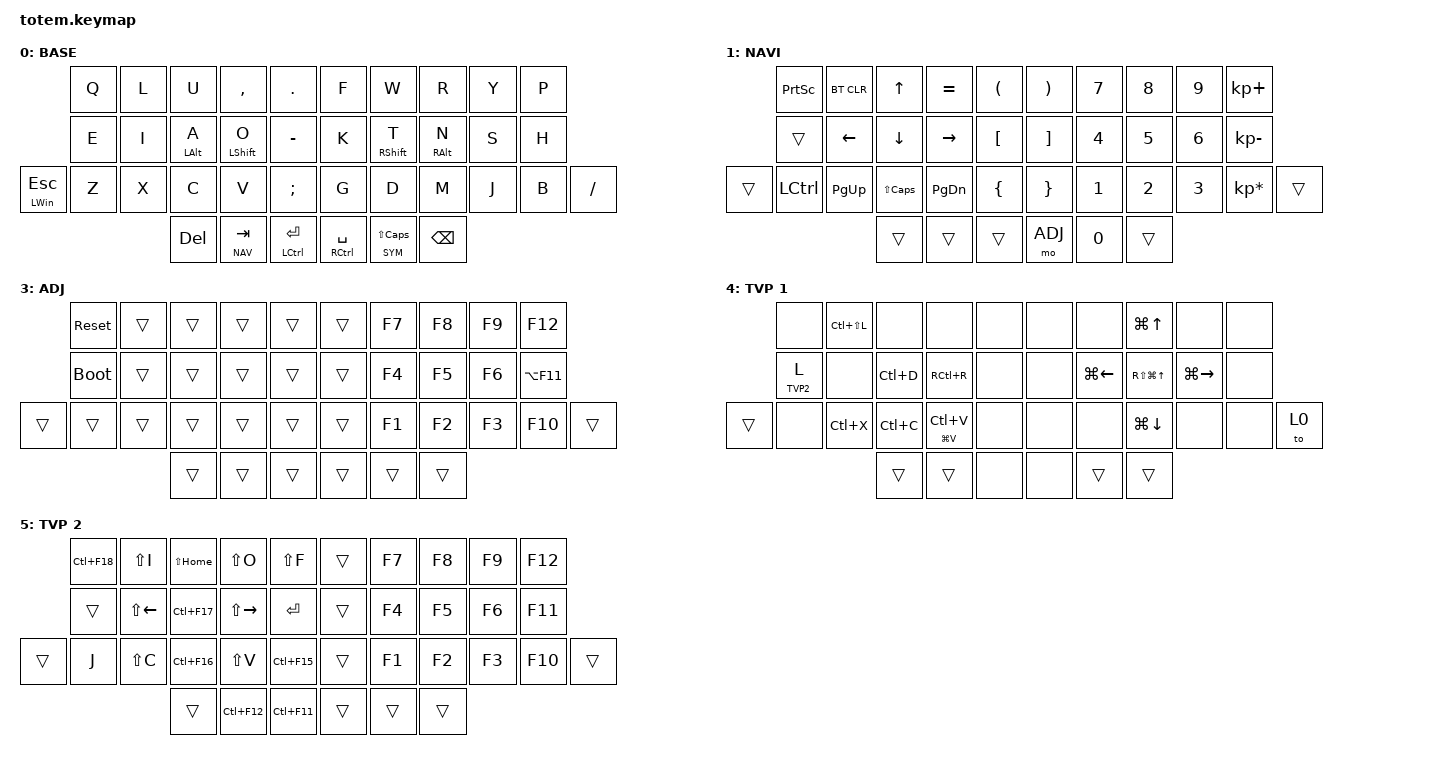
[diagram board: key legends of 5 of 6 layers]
//
//                                                        ▀▀▀▀▀     ▀▀▀▀▀          ▀▀█▀▀
//                                                        ▄▀▀▀▄  ▄  ▄▀▀▀▄  ▄  ▄▀▀▀▄  █  ▄▀▀▀▄
//                                                        █   █  █  █   █  █  █   █  █  █   █
//                                                         ▀▀▀   █   ▀▀▀   █   ▀▀▀   ▀   ▀▀▀
//                                                               █      ▄▄▄█▄▄▄    █   █  
//                                                               ▀      █  █  █     █▄█
//                                                             ▀▀▀▀▀    █  █  █      ▀
//                                                                      ▀  ▀  ▀
//
// ▄▄▄▄▄▄▄▄▄▄▄▄▄▄▄▄▄▄▄▄▄▄▄▄▄▄▄▄▄▄▄▄▄▄▄▄▄▄▄▄▄▄▄▄▄▄▄▄▄▄▄▄▄▄▄▄▄▄▄▄▄▄▄▄▄▄▄▄▄▄▄▄▄▄▄▄▄▄▄▄▄▄▄▄▄▄▄▄▄▄▄▄▄▄▄▄▄▄▄▄▄▄▄▄▄▄▄▄▄▄▄▄▄▄▄▄▄▄▄▄▄▄▄▄▄▄▄▄▄▄▄▄▄▄▄▄▄▄▄▄▄▄▄▄▄▄▄▄▄

#include <behaviors.dtsi>
#include <dt-bindings/zmk/bt.h>
#include <dt-bindings/zmk/keys.h>

#define BASE 0
#define NAV  1
#define SYM  2
#define ADJ  3
#define TVP1 4
#define TVP2 5

&mt {
    quick-tap-ms = <300>;
    global-quick-tap;
    flavor = "tap-preferred";
    tapping-term-ms = <325>;
};

/ {
    combos {
        compatible = "zmk,combos";

        Input_my_PW {
            bindings = <&my_PW>;
            key-positions = <14 15>;
        };

        L0 {
            bindings = <&to 0>;
            key-positions = <10 19>;
        };

        L4 {
            timeout-ms = <100>;
            key-positions = <11 12 13>;
            bindings = <&tog TVP1>;
        };

        ab12 {
            bindings = <&kp LANGUAGE_2>;
            key-positions = <12 13>;
        };

        Hiragana {
            bindings = <&kp LANGUAGE_1>;
            key-positions = <16 17>;
        };

        Orchis {
            bindings = <&kp LC(LA(SPACE))>;
            key-positions = <34 35>;
        };

        TaskMgr {
            bindings = <&kp LC(LS(ESCAPE))>;
            key-positions = <20 31>;
        };

        BT0 {
            bindings = <&bt BT_SEL 0>;
            key-positions = <5 6>;
        };

        BT1 {
            bindings = <&bt BT_SEL 1>;
            key-positions = <15 16>;
        };

        BT2 {
            bindings = <&bt BT_SEL 2>;
            key-positions = <26 27>;
        };

        BT3 {
            bindings = <&bt BT_SEL 3>;
            key-positions = <3 4>;
        };

        egaty1975 {
            bindings = <&egaty1975>;
            key-positions = <4 5>;
        };

        ns_xn {
            bindings = <&ns_xn>;
            key-positions = <17 18>;
        };
    };

    macros {
        my_PW: my_PW {
            compatible = "zmk,behavior-macro";
            #binding-cells = <0>;
            bindings =
                <&macro_tap>,
                <&kp N9 &kp N0 &kp N8 &kp LS(Z) &kp LS(X) &kp LS(C) &kp LS(V) &kp LS(N1) &kp Z &kp X &kp C &kp V>;

            label = "my_PW";
        };

        egaty1975: egaty1975 {
            compatible = "zmk,behavior-macro";
            #binding-cells = <0>;
            bindings =
                <&macro_tap>,
                <&kp N6 &kp N5 &kp N4 &kp Z &kp X &kp C &kp V &kp LS(Z) &kp LS(X) &kp LS(C) &kp LS(V) &kp LS(N1)>;

            label = "EGATY1975";
        };

        ns_xn: ns_xn {
            compatible = "zmk,behavior-macro";
            #binding-cells = <0>;
            bindings = <&macro_tap>, <&kp X &kp N>;

            label = "NS_XN";
        };
    };

    keymap {
        compatible = "zmk,keymap";

        // ▄▄▄▄▄▄▄▄▄▄▄▄▄▄▄▄▄▄▄▄▄▄▄▄▄▄▄▄▄▄▄▄▄▄▄▄▄▄▄▄▄▄▄▄▄▄▄▄▄▄▄▄▄▄▄▄▄▄▄▄▄▄▄▄▄▄▄▄▄▄▄▄▄▄▄▄▄▄▄▄▄▄▄▄▄▄▄▄▄▄▄▄▄▄▄▄▄▄▄▄▄▄▄▄▄▄▄▄▄▄▄▄▄▄▄▄▄▄▄▄▄▄▄▄▄▄▄▄▄▄▄▄▄▄▄▄▄▄▄▄▄▄▄▄▄▄▄▄▄

        base_layer {
            // ┏━━━━━━━━━━━━━━━━━━━━━━━━━━━━━━━━━━━━━━━┓

            label = "BASE";

            // ┗━━━━━━━━━━━━━━━━━━━━━━━━━━━━━━━━━━━━━━━┛
            //             ┏━━━━━━━━━━━┳━━━━━━━━━━━┳━━━━━━━━━━━┳━━━━━━━━━━━┳━━━━━━━━━━━┓   ┏━━━━━━━━━━━┳━━━━━━━━━━━┳━━━━━━━━━━━┳━━━━━━━━━━━┳━━━━━━━━━━━┓
            //             ┃     Q     ┃     W     ┃     F     ┃     P     ┃     G     ┃   ┃     J     ┃     L     ┃     U     ┃     Y     ┃     ;     ┃
            //             ┣━━━━━━━━━━━╋━━━━━━━━━━━╋━━━━━━━━━━━╋━━━━━━━━━━━╋━━━━━━━━━━━┫   ┣━━━━━━━━━━━╋━━━━━━━━━━━╋━━━━━━━━━━━╋━━━━━━━━━━━╋━━━━━━━━━━━┫
            //             ┃     A     ┃     R     ┃     S     ┃     T     ┃     D     ┃   ┃     H     ┃     N     ┃     E     ┃     I     ┃     O     ┃
            // ┏━━━━━━━━━━━╋━━━━━━━━━━━╋━━━━━━━━━━━╋━━━━━━━━━━━╋━━━━━━━━━━━╋━━━━━━━━━━━┫   ┣━━━━━━━━━━━╋━━━━━━━━━━━╋━━━━━━━━━━━╋━━━━━━━━━━━╋━━━━━━━━━━━╋━━━━━━━━━━━┓
            // ┃     Q     ┃     Z     ┃     X     ┃     C     ┃     V     ┃     B     ┃   ┃     K     ┃     M     ┃     ,     ┃     .     ┃     /     ┃     \     ┃
            // ┗━━━━━━━━━━━┻━━━━━━━━━━━┻━━━━━━━━━━━╋━━━━━━━━━━━╋━━━━━━━━━━━╋━━━━━━━━━━━┫   ┣━━━━━━━━━━━╋━━━━━━━━━━━╋━━━━━━━━━━━╋━━━━━━━━━━━┻━━━━━━━━━━━┻━━━━━━━━━━━┛
            //                                     ┃    DEL    ┃    TAB    ┃    SPC    ┃   ┃   ENTER   ┃           ┃   BSPC    ┃
            //                                     ┗━━━━━━━━━━━┻━━━━━━━━━━━┻━━━━━━━━━━━┛   ┗━━━━━━━━━━━┻━━━━━━━━━━━┻━━━━━━━━━━━┛

            bindings = <
                  &kp Q  &kp L  &kp U           &kp COMMA         &kp PERIOD              &kp F                    &kp W              &kp R            &kp Y  &kp P
                  &kp E  &kp I  &mt LEFT_ALT A  &mt LEFT_SHIFT O  &kp MINUS               &kp K                    &mt RIGHT_SHIFT T  &mt RIGHT_ALT N  &kp S  &kp H
&mt LEFT_WIN ESC  &kp Z  &kp X  &kp C           &kp V             &kp SEMICOLON           &kp G                    &kp D              &kp M            &kp J  &kp B  &kp SLASH
                                &kp DELETE      &lt NAV TAB       &mt LEFT_CONTROL RET    &mt RIGHT_CONTROL SPACE  &lt SYM LS(CAPS)   &kp BSPC
            >;
        };

        // ▄▄▄▄▄▄▄▄▄▄▄▄▄▄▄▄▄▄▄▄▄▄▄▄▄▄▄▄▄▄▄▄▄▄▄▄▄▄▄▄▄▄▄▄▄▄▄▄▄▄▄▄▄▄▄▄▄▄▄▄▄▄▄▄▄▄▄▄▄▄▄▄▄▄▄▄▄▄▄▄▄▄▄▄▄▄▄▄▄▄▄▄▄▄▄▄▄▄▄▄▄▄▄▄▄▄▄▄▄▄▄▄▄▄▄▄▄▄▄▄▄▄▄▄▄▄▄▄▄▄▄▄▄▄▄▄▄▄▄▄▄▄▄▄▄▄▄▄▄

        nav_layer {
            // ┏━━━━━━━━━━━━━━━━━━━━━━━━━━━━━━━━━━━━━━━┓

            label = "NAVI";

            // ┗━━━━━━━━━━━━━━━━━━━━━━━━━━━━━━━━━━━━━━━┛
            //             ┏━━━━━━━━━━━┳━━━━━━━━━━━┳━━━━━━━━━━━┳━━━━━━━━━━━┳━━━━━━━━━━━┓   ┏━━━━━━━━━━━┳━━━━━━━━━━━┳━━━━━━━━━━━┳━━━━━━━━━━━┳━━━━━━━━━━━┓
            //             ┃           ┃           ┃     UP    ┃           ┃     {     ┃   ┃     }     ┃     7     ┃     8     ┃     9     ┃     +     ┃
            //             ┣━━━━━━━━━━━╋━━━━━━━━━━━╋━━━━━━━━━━━╋━━━━━━━━━━━╋━━━━━━━━━━━┫   ┣━━━━━━━━━━━╋━━━━━━━━━━━╋━━━━━━━━━━━╋━━━━━━━━━━━╋━━━━━━━━━━━┫
            //             ┃   SHIFT   ┃   LEFT    ┃    DOWN   ┃   RIGHT   ┃     [     ┃   ┃     ]     ┃     4     ┃     5     ┃     6     ┃     -     ┃
            // ┏━━━━━━━━━━━╋━━━━━━━━━━━╋━━━━━━━━━━━╋━━━━━━━━━━━╋━━━━━━━━━━━╋━━━━━━━━━━━┫   ┣━━━━━━━━━━━╋━━━━━━━━━━━╋━━━━━━━━━━━╋━━━━━━━━━━━╋━━━━━━━━━━━╋━━━━━━━━━━━┓
            // ┃           ┃           ┃   P UP    ┃  C LOCK   ┃  P DOWN   ┃     (     ┃   ┃     )     ┃     1     ┃     2     ┃     3     ┃     *     ┃           ┃
            // ┗━━━━━━━━━━━┻━━━━━━━━━━━┻━━━━━━━━━━━╋━━━━━━━━━━━╋━━━━━━━━━━━╋━━━━━━━━━━━┫   ┣━━━━━━━━━━━╋━━━━━━━━━━━╋━━━━━━━━━━━╋━━━━━━━━━━━┻━━━━━━━━━━━┻━━━━━━━━━━━┛
            //                                     ┃           ┃    TAB    ┃    SPC    ┃   ┃    DEL    ┃     0     ┃           ┃
            //                                     ┗━━━━━━━━━━━┻━━━━━━━━━━━┻━━━━━━━━━━━┛   ┗━━━━━━━━━━━┻━━━━━━━━━━━┻━━━━━━━━━━━┛

            bindings = <
        &kp PRINTSCREEN   &bt BT_CLR  &kp UP        &kp EQUAL  &kp LEFT_PARENTHESIS    &kp RIGHT_PARENTHESIS  &kp NUMBER_7  &kp NUMBER_8  &kp NUMBER_9  &kp KP_PLUS
        &trans            &kp LEFT    &kp DOWN      &kp RIGHT  &kp LBKT                &kp RBKT               &kp NUMBER_4  &kp NUMBER_5  &kp NUMBER_6  &kp KP_MINUS
&trans  &kp LEFT_CONTROL  &kp PG_UP   &kp LS(CAPS)  &kp PG_DN  &kp LEFT_BRACE          &kp RIGHT_BRACE        &kp NUMBER_1  &kp NUMBER_2  &kp NUMBER_3  &kp KP_MULTIPLY  &trans
                                      &trans        &trans     &trans                  &mo ADJ                &kp NUMBER_0  &trans
            >;
        };

        // ▄▄▄▄▄▄▄▄▄▄▄▄▄▄▄▄▄▄▄▄▄▄▄▄▄▄▄▄▄▄▄▄▄▄▄▄▄▄▄▄▄▄▄▄▄▄▄▄▄▄▄▄▄▄▄▄▄▄▄▄▄▄▄▄▄▄▄▄▄▄▄▄▄▄▄▄▄▄▄▄▄▄▄▄▄▄▄▄▄▄▄▄▄▄▄▄▄▄▄▄▄▄▄▄▄▄▄▄▄▄▄▄▄▄▄▄▄▄▄▄▄▄▄▄▄▄▄▄▄▄▄▄▄▄▄▄▄▄▄▄▄▄▄▄▄▄▄▄▄

        sim_layer {
            // ┏━━━━━━━━━━━━━━━━━━━━━━━━━━━━━━━━━━━━━━━┓

            label = "SYM";

            // ┗━━━━━━━━━━━━━━━━━━━━━━━━━━━━━━━━━━━━━━━┛
            //             ┏━━━━━━━━━━━┳━━━━━━━━━━━┳━━━━━━━━━━━┳━━━━━━━━━━━┳━━━━━━━━━━━┓   ┏━━━━━━━━━━━┳━━━━━━━━━━━┳━━━━━━━━━━━┳━━━━━━━━━━━┳━━━━━━━━━━━┓
            //             ┃     !     ┃     @     ┃     #     ┃     $     ┃     %     ┃   ┃     ˆ     ┃     &     ┃     Ü     ┃     '     ┃     "     ┃
            //             ┣━━━━━━━━━━━╋━━━━━━━━━━━╋━━━━━━━━━━━╋━━━━━━━━━━━╋━━━━━━━━━━━┫   ┣━━━━━━━━━━━╋━━━━━━━━━━━╋━━━━━━━━━━━╋━━━━━━━━━━━╋━━━━━━━━━━━┫
            //             ┃     Ä     ┃           ┃    SZ     ┃           ┃           ┃   ┃   MUTE    ┃   YEN     ┃   EURO    ┃  POUND    ┃     Ö     ┃
            // ┏━━━━━━━━━━━╋━━━━━━━━━━━╋━━━━━━━━━━━╋━━━━━━━━━━━╋━━━━━━━━━━━╋━━━━━━━━━━━┫   ┣━━━━━━━━━━━╋━━━━━━━━━━━╋━━━━━━━━━━━╋━━━━━━━━━━━╋━━━━━━━━━━━╋━━━━━━━━━━━┓
            // ┃           ┃  EMAIL1   ┃  EMAIL2   ┃           ┃           ┃           ┃   ┃   VOL-    ┃   VOL+    ┃   LAST    ┃   NEXT    ┃     \     ┃           ┃
            // ┗━━━━━━━━━━━┻━━━━━━━━━━━┻━━━━━━━━━━━╋━━━━━━━━━━━╋━━━━━━━━━━━╋━━━━━━━━━━━┫   ┣━━━━━━━━━━━╋━━━━━━━━━━━╋━━━━━━━━━━━╋━━━━━━━━━━━┻━━━━━━━━━━━┻━━━━━━━━━━━┛
            //                                     ┃           ┃           ┃    ADJ    ┃   ┃           ┃           ┃           ┃
            //                                     ┗━━━━━━━━━━━┻━━━━━━━━━━━┻━━━━━━━━━━━┛   ┗━━━━━━━━━━━┻━━━━━━━━━━━┻━━━━━━━━━━━┛

            bindings = <
        &kp EXCL           &kp AT       &kp HASH       &kp DLLR         &kp PRCNT         &kp CARET     &kp AMPS      &kp KP_ASTERISK   &kp SQT     &kp DQT
        &mt LC(HOME) HOME  &kp PAGE_UP  &kp PAGE_DOWN  &mt LC(END) END  &kp INT_HENKAN    &kp C_MUTE    &trans        &kp C_PLAY_PAUSE  &kp PIPE    &kp TILDE
&trans  &trans             &trans       &trans         &trans           &trans            &kp C_VOL_DN  &kp C_VOL_UP  &kp C_PREV        &kp C_NEXT  &kp BSLH   &trans
                                        &trans         &mo ADJ          &trans            &trans        &trans
            >;
        };

        // ▄▄▄▄▄▄▄▄▄▄▄▄▄▄▄▄▄▄▄▄▄▄▄▄▄▄▄▄▄▄▄▄▄▄▄▄▄▄▄▄▄▄▄▄▄▄▄▄▄▄▄▄▄▄▄▄▄▄▄▄▄▄▄▄▄▄▄▄▄▄▄▄▄▄▄▄▄▄▄▄▄▄▄▄▄▄▄▄▄▄▄▄▄▄▄▄▄▄▄▄▄▄▄▄▄▄▄▄▄▄▄▄▄▄▄▄▄▄▄▄▄▄▄▄▄▄▄▄▄▄▄▄▄▄▄▄▄▄▄▄▄▄▄▄▄▄▄▄▄

        adjust_layer {
            // ┏━━━━━━━━━━━━━━━━━━━━━━━━━━━━━━━━━━━━━━━┓

            label = "ADJ";

            // ┗━━━━━━━━━━━━━━━━━━━━━━━━━━━━━━━━━━━━━━━┛
            //             ┏━━━━━━━━━━━┳━━━━━━━━━━━┳━━━━━━━━━━━┳━━━━━━━━━━━┳━━━━━━━━━━━┓   ┏━━━━━━━━━━━┳━━━━━━━━━━━┳━━━━━━━━━━━┳━━━━━━━━━━━┳━━━━━━━━━━━┓
            //             ┃   RESET   ┃ BT CLEAR  ┃  OUT TOG  ┃           ┃           ┃   ┃           ┃    F7     ┃    F8     ┃    F9     ┃    F12    ┃
            //             ┣━━━━━━━━━━━╋━━━━━━━━━━━╋━━━━━━━━━━━╋━━━━━━━━━━━╋━━━━━━━━━━━┫   ┣━━━━━━━━━━━╋━━━━━━━━━━━╋━━━━━━━━━━━╋━━━━━━━━━━━╋━━━━━━━━━━━┫
            //             ┃ BOOTLOAD  ┃ BT NEXT   ┃           ┃           ┃           ┃   ┃           ┃    F4     ┃    F5     ┃    F6     ┃    F11    ┃
            // ┏━━━━━━━━━━━╋━━━━━━━━━━━╋━━━━━━━━━━━╋━━━━━━━━━━━╋━━━━━━━━━━━╋━━━━━━━━━━━┫   ┣━━━━━━━━━━━╋━━━━━━━━━━━╋━━━━━━━━━━━╋━━━━━━━━━━━╋━━━━━━━━━━━╋━━━━━━━━━━━┓
            // ┃           ┃           ┃ BT PREV   ┃           ┃           ┃           ┃   ┃           ┃    F1     ┃    F2     ┃    F3     ┃    F10    ┃           ┃
            // ┗━━━━━━━━━━━┻━━━━━━━━━━━┻━━━━━━━━━━━╋━━━━━━━━━━━╋━━━━━━━━━━━╋━━━━━━━━━━━┫   ┣━━━━━━━━━━━╋━━━━━━━━━━━╋━━━━━━━━━━━╋━━━━━━━━━━━┻━━━━━━━━━━━┻━━━━━━━━━━━┛
            //                                     ┃           ┃           ┃           ┃   ┃           ┃           ┃           ┃
            //                                     ┗━━━━━━━━━━━┻━━━━━━━━━━━┻━━━━━━━━━━━┛   ┗━━━━━━━━━━━┻━━━━━━━━━━━┻━━━━━━━━━━━┛

            bindings = <
        &sys_reset   &trans  &trans  &trans  &trans    &trans  &kp F7  &kp F8  &kp F9  &kp F12
        &bootloader  &trans  &trans  &trans  &trans    &trans  &kp F4  &kp F5  &kp F6  &kp LA(F11)
&trans  &trans       &trans  &trans  &trans  &trans    &trans  &kp F1  &kp F2  &kp F3  &kp F10      &trans
                             &trans  &trans  &trans    &trans  &trans  &trans
            >;
        };

        // ▄▄▄▄▄▄▄▄▄▄▄▄▄▄▄▄▄▄▄▄▄▄▄▄▄▄▄▄▄▄▄▄▄▄▄▄▄▄▄▄▄▄▄▄▄▄▄▄▄▄▄▄▄▄▄▄▄▄▄▄▄▄▄▄▄▄▄▄▄▄▄▄▄▄▄▄▄▄▄▄▄▄▄▄▄▄▄▄▄▄▄▄▄▄▄▄▄▄▄▄▄▄▄▄▄▄▄▄▄▄▄▄▄▄▄▄▄▄▄▄▄▄▄▄▄▄▄▄▄▄▄▄▄▄▄▄▄▄▄▄▄▄▄▄▄▄▄▄▄

        tvp1_layer {
            // ┏━━━━━━━━━━━━━━━━━━━━━━━━━━━━━━━━━━━━━━━┓

            label = "TVP 1";

            // ┗━━━━━━━━━━━━━━━━━━━━━━━━━━━━━━━━━━━━━━━┛
            //             ┏━━━━━━━━━━━┳━━━━━━━━━━━┳━━━━━━━━━━━┳━━━━━━━━━━━┳━━━━━━━━━━━┓   ┏━━━━━━━━━━━┳━━━━━━━━━━━┳━━━━━━━━━━━┳━━━━━━━━━━━┳━━━━━━━━━━━┓
            //             ┃ NEXT FILE ┃ MARK IN   ┃ ROTATE    ┃ MARK OUT  ┃ SHOW SNAP ┃   ┃           ┃           ┃           ┃           ┃           ┃
            //             ┣━━━━━━━━━━━╋━━━━━━━━━━━╋━━━━━━━━━━━╋━━━━━━━━━━━╋━━━━━━━━━━━┫   ┣━━━━━━━━━━━╋━━━━━━━━━━━╋━━━━━━━━━━━╋━━━━━━━━━━━╋━━━━━━━━━━━┫
            //             ┃ TVP II    ┃ LEFT      ┃ PAN       ┃ RIGHT     ┃ PLAY/FLIP ┃   ┃           ┃           ┃           ┃           ┃           ┃
            // ┏━━━━━━━━━━━╋━━━━━━━━━━━╋━━━━━━━━━━━╋━━━━━━━━━━━╋━━━━━━━━━━━╋━━━━━━━━━━━┫   ┣━━━━━━━━━━━╋━━━━━━━━━━━╋━━━━━━━━━━━╋━━━━━━━━━━━╋━━━━━━━━━━━╋━━━━━━━━━━━┓
            // ┃ FULLSCR   ┃ SHIFT     ┃ COPY      ┃ DELETE    ┃ PASTE     ┃ IMG MARK  ┃   ┃           ┃           ┃           ┃           ┃           ┃           ┃
            // ┗━━━━━━━━━━━┻━━━━━━━━━━━┻━━━━━━━━━━━╋━━━━━━━━━━━╋━━━━━━━━━━━╋━━━━━━━━━━━┫   ┣━━━━━━━━━━━╋━━━━━━━━━━━╋━━━━━━━━━━━╋━━━━━━━━━━━┻━━━━━━━━━━━┻━━━━━━━━━━━┛
            //                                     ┃           ┃ UNDO/SAVE ┃  SEL/MOV  ┃   ┃           ┃           ┃           ┃
            //                                     ┗━━━━━━━━━━━┻━━━━━━━━━━━┻━━━━━━━━━━━┛   ┗━━━━━━━━━━━┻━━━━━━━━━━━┻━━━━━━━━━━━┛

            bindings = <
        &none       &kp LC(LS(L))  &none      &none            &none    &none  &none         &kp LG(UP)      &none          &none
        &lt TVP2 L  &none          &kp LC(D)  &kp RC(R)        &none    &none  &kp LG(LEFT)  &kp RS(LG(UP))  &kp LG(RIGHT)  &none
&trans  &none       &kp LC(X)      &kp LC(C)  &mt LG(V) LC(V)  &none    &none  &none         &kp LG(DOWN)    &none          &none  &to 0
                                   &trans     &trans           &none    &none  &trans        &trans
            >;
        };

        // ▄▄▄▄▄▄▄▄▄▄▄▄▄▄▄▄▄▄▄▄▄▄▄▄▄▄▄▄▄▄▄▄▄▄▄▄▄▄▄▄▄▄▄▄▄▄▄▄▄▄▄▄▄▄▄▄▄▄▄▄▄▄▄▄▄▄▄▄▄▄▄▄▄▄▄▄▄▄▄▄▄▄▄▄▄▄▄▄▄▄▄▄▄▄▄▄▄▄▄▄▄▄▄▄▄▄▄▄▄▄▄▄▄▄▄▄▄▄▄▄▄▄▄▄▄▄▄▄▄▄▄▄▄▄▄▄▄▄▄▄▄▄▄▄▄▄▄▄▄

        tvp2_layer {
            // ┏━━━━━━━━━━━━━━━━━━━━━━━━━━━━━━━━━━━━━━━┓

            label = "TVP 2";

            // ┗━━━━━━━━━━━━━━━━━━━━━━━━━━━━━━━━━━━━━━━┛
            //             ┏━━━━━━━━━━━┳━━━━━━━━━━━┳━━━━━━━━━━━┳━━━━━━━━━━━┳━━━━━━━━━━━┓   ┏━━━━━━━━━━━┳━━━━━━━━━━━┳━━━━━━━━━━━┳━━━━━━━━━━━┳━━━━━━━━━━━┓
            //             ┃ SOLO      ┃ TOGGLE IN ┃ RESET ROT ┃ TOGGLE OUT┃ TAKE SNAP ┃   ┃           ┃           ┃           ┃           ┃           ┃
            //             ┣━━━━━━━━━━━╋━━━━━━━━━━━╋━━━━━━━━━━━╋━━━━━━━━━━━╋━━━━━━━━━━━┫   ┣━━━━━━━━━━━╋━━━━━━━━━━━╋━━━━━━━━━━━╋━━━━━━━━━━━╋━━━━━━━━━━━┫
            //             ┃ ---       ┃ LAST KEY  ┃ NEW KEY   ┃ NEXT KEY  ┃ ENTER     ┃   ┃           ┃           ┃           ┃           ┃           ┃
            // ┏━━━━━━━━━━━╋━━━━━━━━━━━╋━━━━━━━━━━━╋━━━━━━━━━━━╋━━━━━━━━━━━╋━━━━━━━━━━━┫   ┣━━━━━━━━━━━╋━━━━━━━━━━━╋━━━━━━━━━━━╋━━━━━━━━━━━╋━━━━━━━━━━━╋━━━━━━━━━━━┓
            // ┃           ┃ FULLSCR   ┃ CPY2BRUSH ┃ DEL HEAD  ┃ PSTinPLACE┃ BOOK MARK ┃   ┃           ┃           ┃           ┃           ┃           ┃           ┃
            // ┗━━━━━━━━━━━┻━━━━━━━━━━━┻━━━━━━━━━━━╋━━━━━━━━━━━╋━━━━━━━━━━━╋━━━━━━━━━━━┫   ┣━━━━━━━━━━━╋━━━━━━━━━━━╋━━━━━━━━━━━╋━━━━━━━━━━━┻━━━━━━━━━━━┻━━━━━━━━━━━┛
            //                                     ┃           ┃ REDO/SAV1 ┃TRANS/WARP ┃   ┃           ┃           ┃           ┃
            //                                     ┗━━━━━━━━━━━┻━━━━━━━━━━━┻━━━━━━━━━━━┛   ┗━━━━━━━━━━━┻━━━━━━━━━━━┻━━━━━━━━━━━┛

            bindings = <
        &kp LC(F18)  &kp LS(I)     &kp LS(HOME)  &kp LS(O)      &kp LS(F)      &trans  &kp F7  &kp F8  &kp F9  &kp F12
        &trans       &kp LS(LEFT)  &kp LC(F17)   &kp LS(RIGHT)  &kp RET        &trans  &kp F4  &kp F5  &kp F6  &kp F11
&trans  &kp J        &kp LS(C)     &kp LC(F16)   &kp LS(V)      &kp LC(F15)    &trans  &kp F1  &kp F2  &kp F3  &kp F10  &trans
                                   &trans        &kp LC(F12)    &kp LC(F11)    &trans  &trans  &trans
            >;
        };
    };
};
